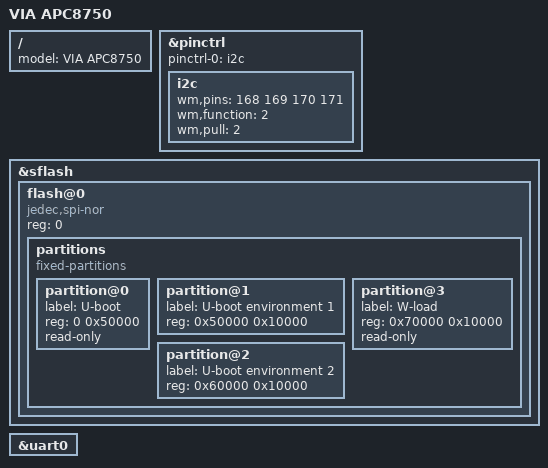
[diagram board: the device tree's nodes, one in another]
// SPDX-License-Identifier: GPL-2.0-or-later
/*
 * wm8750-apc8750.dts
 *  - Device tree file for VIA APC8750
 *
 * Copyright (C) 2012 Tony Prisk <linux@prisktech.co.nz>
 */

/dts-v1/;
/include/ "wm8750.dtsi"

/ {
	model = "VIA APC8750";
};

&pinctrl {
	pinctrl-names = "default";
	pinctrl-0 = <&i2c>;

	i2c: i2c {
		wm,pins = <168 169 170 171>;
		wm,function = <2>;	/* alt */
		wm,pull = <2>;	/* pull-up */
	};
};

&sflash {
	status = "okay";

	flash@0 {
		compatible = "jedec,spi-nor";
		reg = <0>;

		partitions {
			compatible = "fixed-partitions";
			#address-cells = <1>;
			#size-cells = <1>;

			partition@0 {
				label = "U-boot";
				reg = <0 0x50000>;
				read-only;
			};

			partition@1 {
				label = "U-boot environment 1";
				reg = <0x50000 0x10000>;
			};

			partition@2 {
				label = "U-boot environment 2";
				reg = <0x60000 0x10000>;
			};

			partition@3 {
				label = "W-load";
				reg = <0x70000 0x10000>;
				read-only;
			};
		};
	};
};

&uart0 {
	status = "okay";
};
